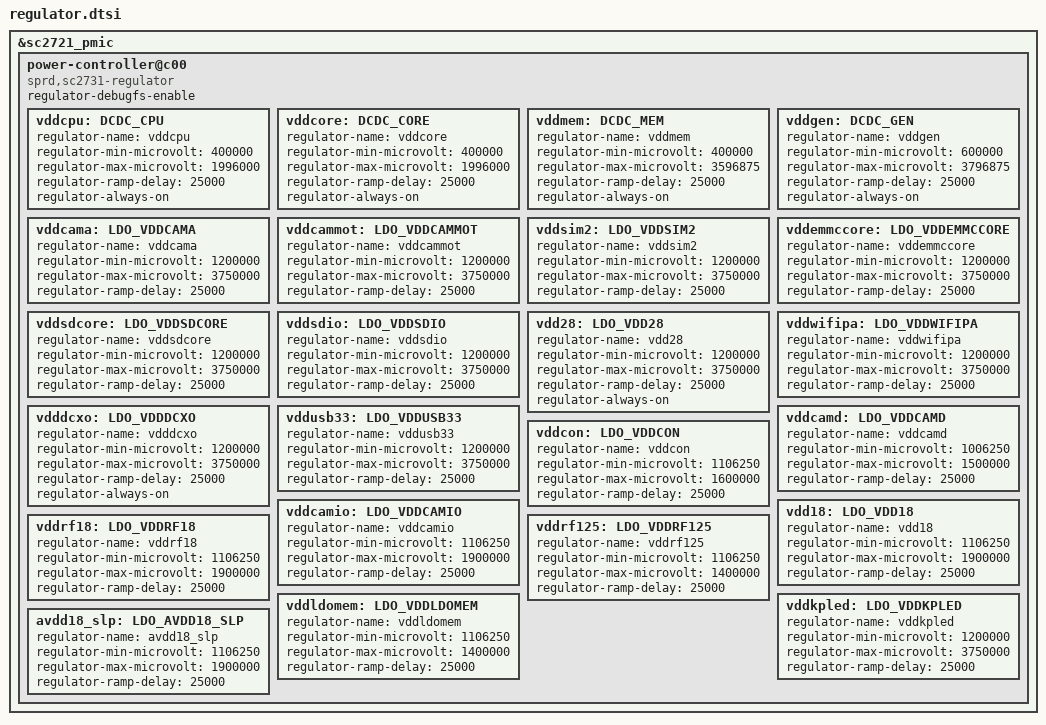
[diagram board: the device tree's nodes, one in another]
// SPDX-License-Identifier: (GPL-2.0+ OR MIT)
/*
 * Unisoc SC2730 PMIC dts file
 *
 * Copyright (C) 2020, Unisoc Inc.
 *
 */

&sc2721_pmic {
	power-controller@c00 {
		compatible = "sprd,sc2731-regulator", "sprd,sc2721-regulator";
		regulator-debugfs-enable;

		vddcpu: DCDC_CPU {
			regulator-name = "vddcpu";
			regulator-min-microvolt = <400000>;
			regulator-max-microvolt = <1996000>;
			regulator-ramp-delay = <25000>;
			regulator-always-on;
		};

		vddcore: DCDC_CORE {
			regulator-name = "vddcore";
			regulator-min-microvolt = <400000>;
			regulator-max-microvolt = <1996000>;
			regulator-ramp-delay = <25000>;
			regulator-always-on;
		};

		vddmem: DCDC_MEM {
			regulator-name = "vddmem";
			regulator-min-microvolt = <400000>;
			regulator-max-microvolt = <3596875>;
			regulator-ramp-delay = <25000>;
			regulator-always-on;
		};

		vddgen: DCDC_GEN {
			regulator-name = "vddgen";
			regulator-min-microvolt = <600000>;
			regulator-max-microvolt = <3796875>;
			regulator-ramp-delay = <25000>;
			regulator-always-on;
		};

		vddcama: LDO_VDDCAMA {
			regulator-name = "vddcama";
			regulator-min-microvolt = <1200000>;
			regulator-max-microvolt = <3750000>;
			regulator-ramp-delay = <25000>;
		};

		vddcammot: LDO_VDDCAMMOT {
			regulator-name = "vddcammot";
			regulator-min-microvolt = <1200000>;
			regulator-max-microvolt = <3750000>;
			regulator-ramp-delay = <25000>;
		};

		vddsim2: LDO_VDDSIM2 {
			regulator-name = "vddsim2";
			regulator-min-microvolt = <1200000>;
			regulator-max-microvolt = <3750000>;
			regulator-ramp-delay = <25000>;
		};

		vddemmccore: LDO_VDDEMMCCORE {
			regulator-name = "vddemmccore";
			regulator-min-microvolt = <1200000>;
			regulator-max-microvolt = <3750000>;
			regulator-ramp-delay = <25000>;
		};

		vddsdcore: LDO_VDDSDCORE {
			regulator-name = "vddsdcore";
			regulator-min-microvolt = <1200000>;
			regulator-max-microvolt = <3750000>;
			regulator-ramp-delay = <25000>;
		};

		vddsdio: LDO_VDDSDIO {
			regulator-name = "vddsdio";
			regulator-min-microvolt = <1200000>;
				regulator-max-microvolt = <3750000>;
			regulator-ramp-delay = <25000>;
		};

		vdd28: LDO_VDD28 {
			regulator-name = "vdd28";
			regulator-min-microvolt = <1200000>;
			regulator-max-microvolt = <3750000>;
			regulator-ramp-delay = <25000>;
			regulator-always-on;
		};

		vddwifipa: LDO_VDDWIFIPA {
			regulator-name = "vddwifipa";
			regulator-min-microvolt = <1200000>;
			regulator-max-microvolt = <3750000>;
			regulator-ramp-delay = <25000>;
		};

		vdddcxo: LDO_VDDDCXO {
			regulator-name = "vdddcxo";
			regulator-min-microvolt = <1200000>;
			regulator-max-microvolt = <3750000>;
			regulator-ramp-delay = <25000>;
			regulator-always-on;
		};

		vddusb33: LDO_VDDUSB33 {
			regulator-name = "vddusb33";
			regulator-min-microvolt = <1200000>;
			regulator-max-microvolt = <3750000>;
			regulator-ramp-delay = <25000>;
		};

		vddcamd: LDO_VDDCAMD {
			regulator-name = "vddcamd";
			regulator-min-microvolt = <1006250>;
			regulator-max-microvolt = <1500000>;
			regulator-ramp-delay = <25000>;
		};

		vddcon: LDO_VDDCON {
			regulator-name = "vddcon";
			regulator-min-microvolt = <1106250>;
			regulator-max-microvolt = <1600000>;
			regulator-ramp-delay = <25000>;
		};

		vddcamio: LDO_VDDCAMIO {
			regulator-name = "vddcamio";
			regulator-min-microvolt = <1106250>;
			regulator-max-microvolt = <1900000>;
			regulator-ramp-delay = <25000>;
		};

		vdd18: LDO_VDD18 {
			regulator-name = "vdd18";
			regulator-min-microvolt = <1106250>;
			regulator-max-microvolt = <1900000>;
			regulator-ramp-delay = <25000>;
		};

		vddrf18: LDO_VDDRF18 {
			regulator-name = "vddrf18";
			regulator-min-microvolt = <1106250>;
			regulator-max-microvolt = <1900000>;
			regulator-ramp-delay = <25000>;
		};

		vddrf125: LDO_VDDRF125 {
			regulator-name = "vddrf125";
			regulator-min-microvolt = <1106250>;
			regulator-max-microvolt = <1400000>;
			regulator-ramp-delay = <25000>;
		};

		vddldomem: LDO_VDDLDOMEM {
			regulator-name = "vddldomem";
			regulator-min-microvolt = <1106250>;
			regulator-max-microvolt = <1400000>;
			regulator-ramp-delay = <25000>;
		};

		vddkpled: LDO_VDDKPLED {
			regulator-name = "vddkpled";
			regulator-min-microvolt = <1200000>;
			regulator-max-microvolt = <3750000>;
			regulator-ramp-delay = <25000>;
		};

		avdd18_slp: LDO_AVDD18_SLP {
			regulator-name = "avdd18_slp";
			regulator-min-microvolt = <1106250>;
			regulator-max-microvolt = <1900000>;
			regulator-ramp-delay = <25000>;
		};
	};

};
